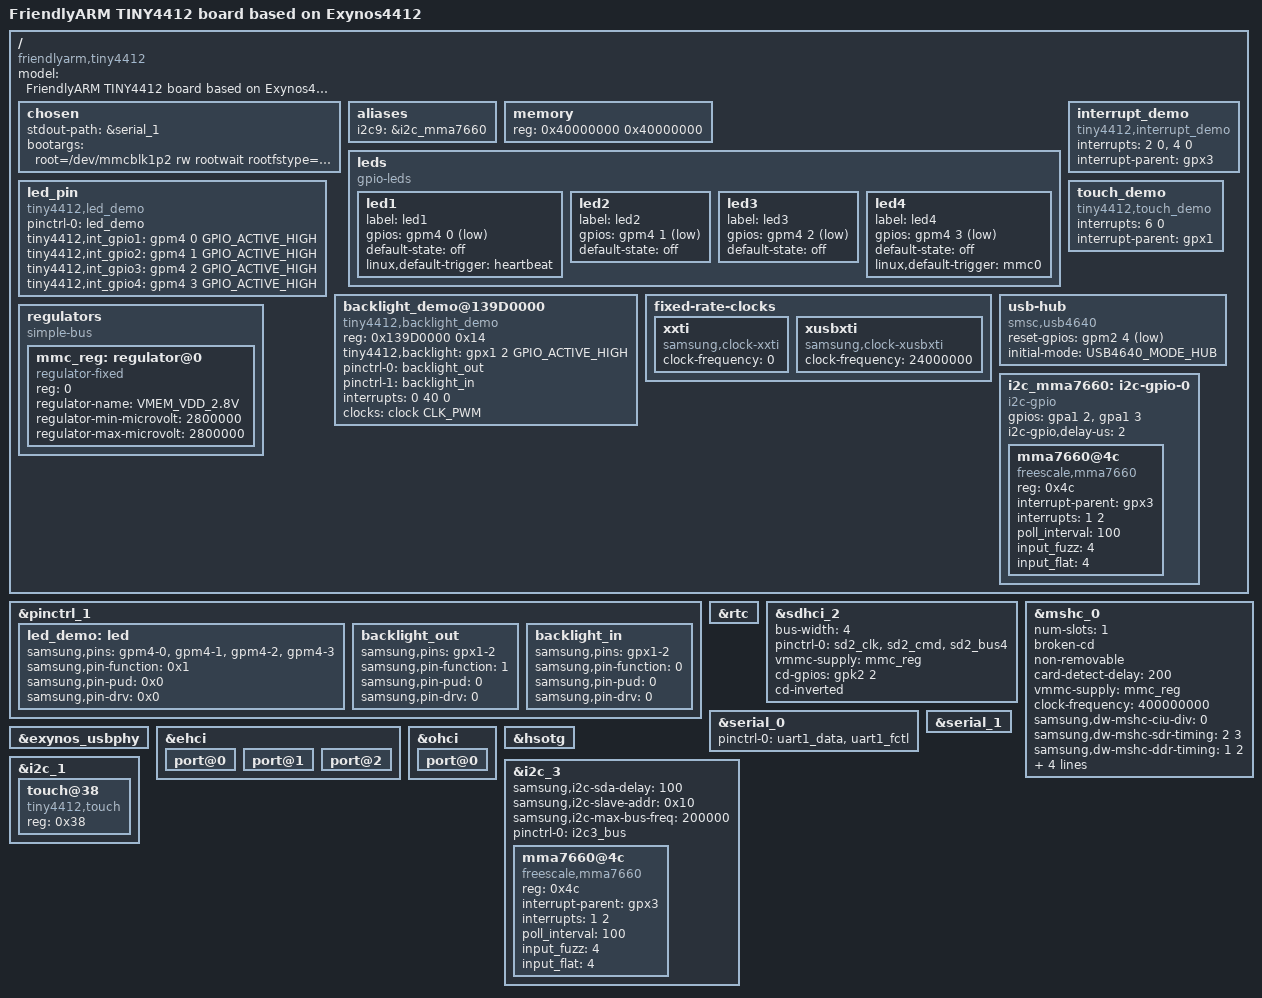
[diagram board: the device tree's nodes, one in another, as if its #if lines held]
/*
 * FriendlyARM's Exynos4412 based TINY4412 board device tree source
 *
 * Copyright (c) 2013 Alex Ling <kasimling@gmail.com>
 *
 * Device tree source file for FriendlyARM's TINY4412 board which is based on
 * Samsung's Exynos4412 SoC.
 *
 * This program is free software; you can redistribute it and/or modify
 * it under the terms of the GNU General Public License version 2 as
 * published by the Free Software Foundation.
*/

/dts-v1/;
#include "exynos4412.dtsi"
#include <dt-bindings/gpio/gpio.h>
#include <dt-bindings/usb4640/usb4640.h>
#include <dt-bindings/pwm/pwm.h>
#include <autoconf.h>

/ {
	model = "FriendlyARM TINY4412 board based on Exynos4412";
	compatible = "friendlyarm,tiny4412", "samsung,exynos4412", "samsung,exynos4";

	chosen {
		stdout-path = &serial_1;
		bootargs = "root=/dev/mmcblk1p2 rw rootwait rootfstype=ext3 console=ttySAC0,115200 ethmac=1C:6F:65:34:51:7E init=/linuxrc";
	};

	aliases {
#ifdef CONFIG_MMA7660_USE_I2C_GPIO
		i2c9 = &i2c_mma7660;
#endif
        };

	memory {
		reg = <0x40000000 0x40000000>;
	};

	leds {
		compatible = "gpio-leds";

		led1 {
			label = "led1";
			gpios = <&gpm4 0 GPIO_ACTIVE_LOW>;
			default-state = "off";
			linux,default-trigger = "heartbeat";
		};

		led2 {
			label = "led2";
			gpios = <&gpm4 1 GPIO_ACTIVE_LOW>;
			default-state = "off";
		};

		led3 {
			label = "led3";
			gpios = <&gpm4 2 GPIO_ACTIVE_LOW>;
			default-state = "off";
		};

		led4 {
			label = "led4";
			gpios = <&gpm4 3 GPIO_ACTIVE_LOW>;
			default-state = "off";
			linux,default-trigger = "mmc0";
		};
	};

led_pin {
    compatible         = "tiny4412,led_demo";
    pinctrl-names = "led_demo";
    pinctrl-0 = <&led_demo>;
    tiny4412,int_gpio1 = <&gpm4 0 GPIO_ACTIVE_HIGH>;
    tiny4412,int_gpio2 = <&gpm4 1 GPIO_ACTIVE_HIGH>;
    tiny4412,int_gpio3 = <&gpm4 2 GPIO_ACTIVE_HIGH>;
    tiny4412,int_gpio4 = <&gpm4 3 GPIO_ACTIVE_HIGH>;
};

  interrupt_demo:interrupt_demo{
      compatible = "tiny4412,interrupt_demo";
      interrupts = <2 0>,<4 0>;
      interrupt-parent = <&gpx3>;
  };

touch_demo{
    compatible = "tiny4412,touch_demo";
    interrupts = <6 0>;
        interrupt-parent = <&gpx1>;
        status = "okay";
};
backlight_demo@139D0000{
                compatible         = "tiny4412,backlight_demo";
                reg = <0x139D0000  0x14>;
                tiny4412,backlight = <&gpx1 2 GPIO_ACTIVE_HIGH>;
                pinctrl-names = "backlight_out","backlight_in";
                pinctrl-0 = <&backlight_out>;
                pinctrl-1 = <&backlight_in>;
                interrupts = <0 40 0>;
                clocks = <&clock CLK_PWM>;
                clock-names = "timers";
        };

#if 0
pwm_demo@139D0000{
    compatible         = "tiny4412,pwm_demo";
    reg = <0x139D0000  0x14>;
    pinctrl-names = "default";
    //这里可以设置为pinctrl-names = "default";代码中就免去 devm_pinctrl_get ...等等操作了
    pinctrl-0 = <&pwm0_out>;
    clocks = <&clock CLK_PWM>;
    //PWM ADC 等等模块都需要使能时钟模块才能工作,CLK_PWM定义在Exynos4.h (include\dt-bindings\clock) 
    clock-names = "timers";
};
#endif

	fixed-rate-clocks {
		xxti {
			compatible = "samsung,clock-xxti";
			clock-frequency = <0>;
		};

		xusbxti {
			compatible = "samsung,clock-xusbxti";
			clock-frequency = <24000000>;
		};
	};

	usb-hub {
		compatible = "smsc,usb4640";
		reset-gpios = <&gpm2 4 GPIO_ACTIVE_LOW>;
		initial-mode = <USB4640_MODE_HUB>;
	};

	regulators {
		compatible = "simple-bus";
		#address-cells = <1>;
		#size-cells = <0>;

		mmc_reg: regulator@0{
			compatible = "regulator-fixed";
			reg = <0>;
			regulator-name = "VMEM_VDD_2.8V";
			regulator-min-microvolt = <2800000>;
			regulator-max-microvolt = <2800000>;
		};
	};


#ifdef CONFIG_MMA7660_USE_I2C_GPIO
	i2c_mma7660: i2c-gpio-0 {
		compatible = "i2c-gpio";
		gpios = <&gpa1 2 GPIO_ACTIVE_HIGH>,    /* SDA */
			<&gpa1 3 GPIO_ACTIVE_HIGH>;    /* SCL */
		/* i2c-gpio,sda-open-drain; */
		/* i2c-gpio,scl-open-drain; */
		i2c-gpio,delay-us = <2>;  /* 250 kHz  */
		#address-cells = <1>;
		#size-cells = <0>;
		status = "okay";

		mma7660@4c {
			compatible = "freescale,mma7660";
			reg = <0x4c>;
			interrupt-parent = <&gpx3>;
			interrupts = <1 2>;
			poll_interval = <100>;
			input_fuzz = <4>;
			input_flat = <4>;
			status = "okay";
		};
	};
#endif
};

&pinctrl_1 {
        led_demo: led{
                samsung,pins = "gpm4-0", "gpm4-1" ,"gpm4-2", "gpm4-3";
                samsung,pin-function = <0x1>;  
                samsung,pin-pud = <0x0>;      
                samsung,pin-drv = <0x0>;     
        };
}; 

&pinctrl_1 {
        backlight_out: backlight_out{
                samsung,pins = "gpx1-2";
                samsung,pin-function = <1>;
                samsung,pin-pud = <0>;
                samsung,pin-drv = <0>;
        };
         backlight_in: backlight_in{
                samsung,pins = "gpx1-2";
                samsung,pin-function = <0>;
                samsung,pin-pud = <0>;
                samsung,pin-drv = <0>;
        };
};


&rtc {
	status = "okay";
};

&sdhci_2 {
	bus-width = <4>;
	pinctrl-0 = <&sd2_clk &sd2_cmd &sd2_bus4>;
	pinctrl-names = "default";
	vmmc-supply = <&mmc_reg>;
	cd-gpios = <&gpk2 2 GPIO_ACTIVE_HIGH>;
	cd-inverted;
	status = "okay";
};

&mshc_0 {
	num-slots = <1>;
	broken-cd;
	non-removable;
	card-detect-delay = <200>;
	vmmc-supply = <&mmc_reg>;
	clock-frequency = <400000000>;
	samsung,dw-mshc-ciu-div = <0>;
	samsung,dw-mshc-sdr-timing = <2 3>;
	samsung,dw-mshc-ddr-timing = <1 2>;
	pinctrl-0 = <&sd4_clk &sd4_cmd &sd4_bus4 &sd4_bus8>;
	pinctrl-names = "default";
	status = "okay";
	bus-width = <8>;
	cap-mmc-highspeed;
};

&serial_0 {
	pinctrl-names = "default";
	pinctrl-0 = <&uart1_data &uart1_fctl>;
	status = "okay";
};

&serial_1 {
	status = "okay";
};

&exynos_usbphy {
	status = "okay";
};

&ehci {
	status = "okay";
	port@0 {
		status = "okay";
	};
	port@1 {
		status = "okay";
	};
	port@2 {
		status = "okay";
	};
};

&ohci {
	status = "okay";
	port@0 {
		status = "okay";
	};
};

&hsotg {
	status = "okay";
};
&i2c_1{
        status = "okay";
        touch@38{
                compatible = "tiny4412,touch";
                reg = <0x38>;
        };
};
#ifndef CONFIG_MMA7660_USE_I2C_GPIO
/* MMA7660FC  */
&i2c_3 {
	samsung,i2c-sda-delay = <100>;
	samsung,i2c-slave-addr = <0x10>;
	samsung,i2c-max-bus-freq = <200000>;
	pinctrl-0 = <&i2c3_bus>;
	pinctrl-names = "default";
	status = "okay";

	mma7660@4c {
		compatible = "freescale,mma7660";
		reg = <0x4c>;
		interrupt-parent = <&gpx3>;
		interrupts = <1 2>;
		poll_interval = <100>;
		input_fuzz = <4>;
		input_flat = <4>;
		status = "okay";
	};
};
#endif

